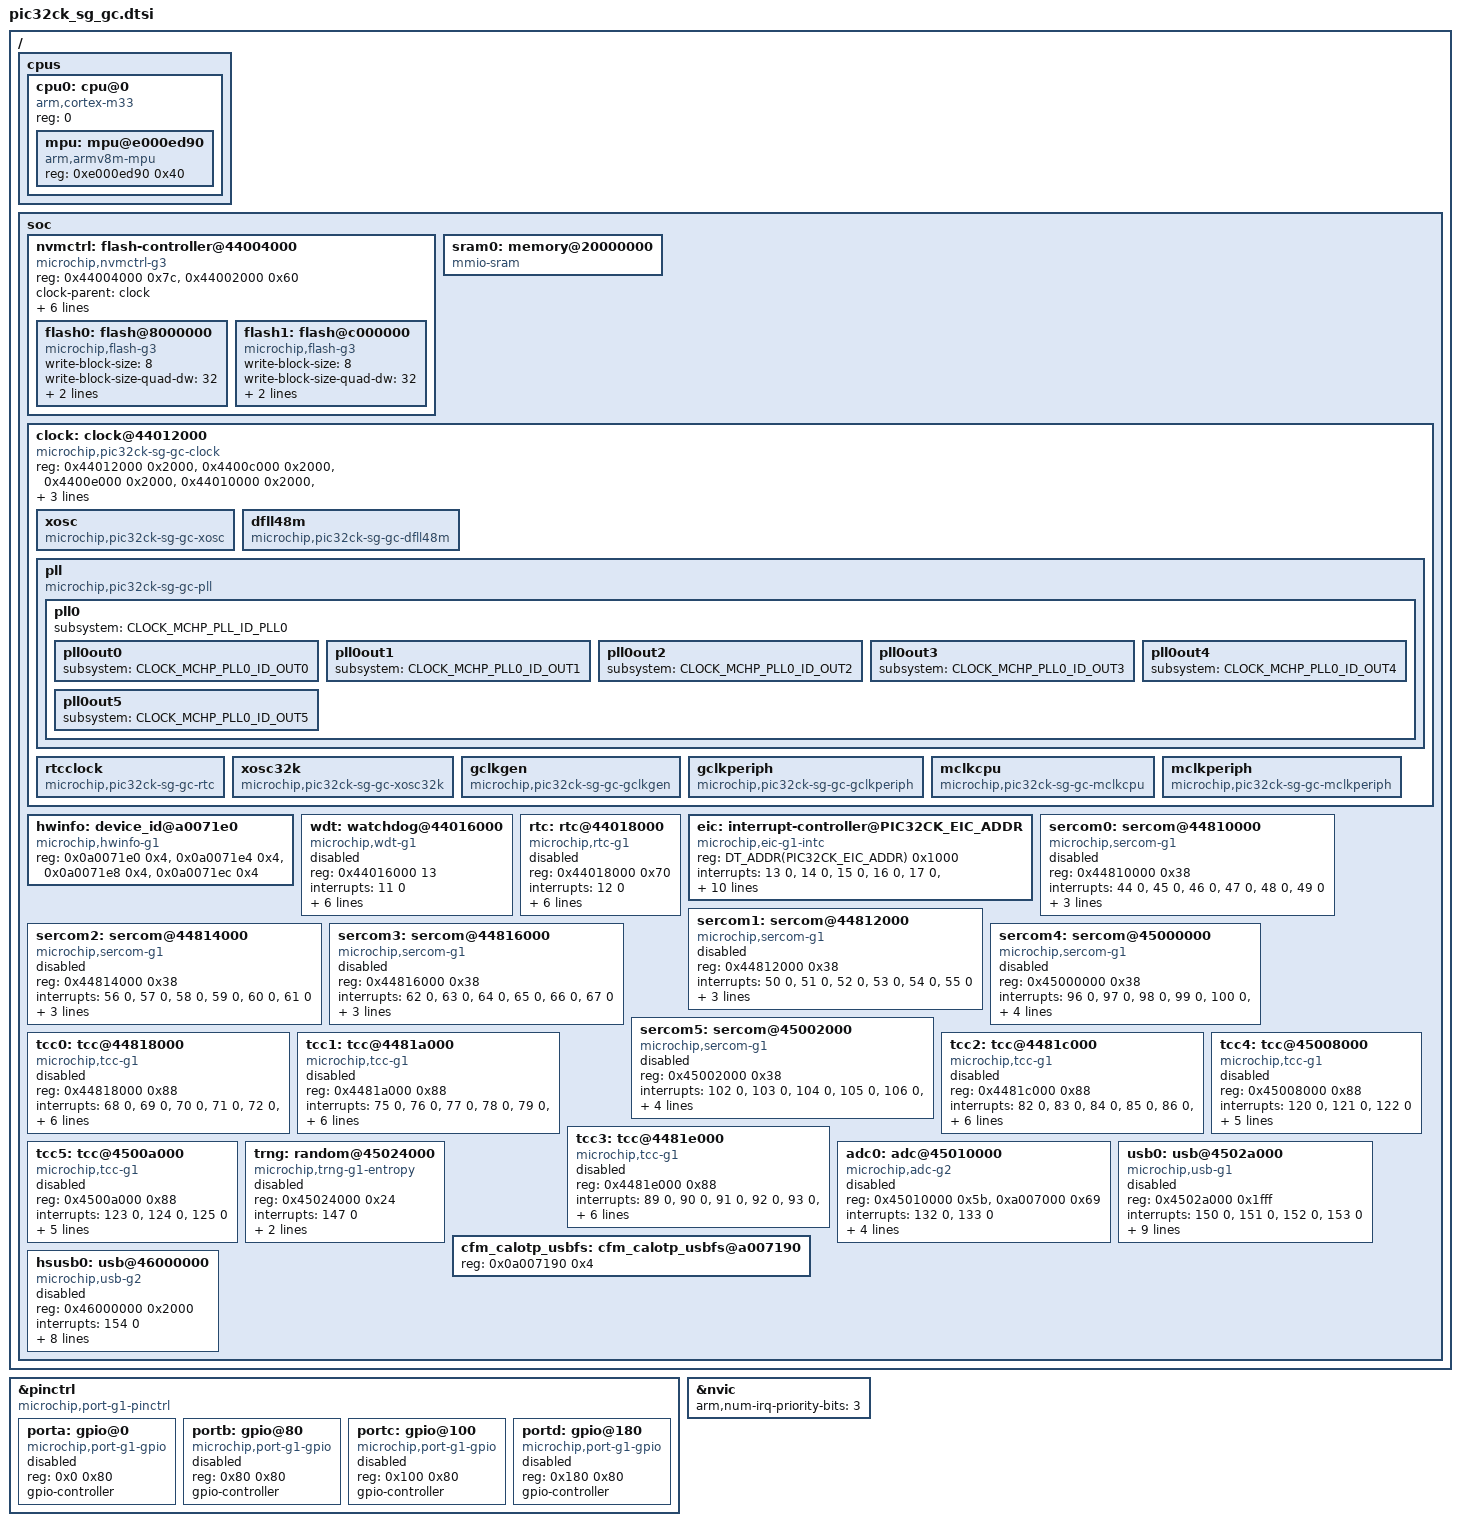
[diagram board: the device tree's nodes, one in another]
/*
 * Copyright (c) 2026 Microchip Technology Inc.
 *
 * SPDX-License-Identifier: Apache-2.0
 */

#include <arm/armv8-m.dtsi>
#include <zephyr/dt-bindings/gpio/gpio.h>
#include <zephyr/dt-bindings/clock/mchp_pic32ck_sg_gc_clock.h>

/* EIC alias the CPU uses; SG parts override it with the secure one (pic32ck_sg.dtsi). */
#ifndef PIC32CK_EIC_ADDR
#define PIC32CK_EIC_ADDR 4401a000
#endif

/ {
	cpus {
		#address-cells = <1>;
		#size-cells = <0>;

		cpu0: cpu@0 {
			device_type = "cpu";
			compatible = "arm,cortex-m33";
			reg = <0>;
			#address-cells = <1>;
			#size-cells = <1>;

			mpu: mpu@e000ed90 {
				compatible = "arm,armv8m-mpu";
				reg = <0xe000ed90 0x40>; /* 64 bytes for ARMv8-M MPU */
			};
		};
	};

	soc {
		nvmctrl: flash-controller@44004000 {
			compatible = "microchip,nvmctrl-g3";
			reg = <0x44004000 0x7c>, <0x44002000 0x60>;
			reg-names = "fcw", "fcr";
			clock-parent = <&clock>;
			clocks = <&mclkperiph CLOCK_MCHP_MCLKPERIPH_ID_FCW_AHB>,
				 <&mclkperiph CLOCK_MCHP_MCLKPERIPH_ID_FCW_APB>,
				 <&mclkperiph CLOCK_MCHP_MCLKPERIPH_ID_FCR_AHB>,
				 <&mclkperiph CLOCK_MCHP_MCLKPERIPH_ID_FCR_APB>;
			clock-names = "mclk-fcw-ahb", "mclk-fcw-apb", "mclk-fcr-ahb",
				      "mclk-fcr-apb";
			interrupts = <0 0>, <1 0>, <2 0>;
			interrupt-names = "eccerr", "crcerr", "fcw";
			#address-cells = <1>;
			#size-cells = <1>;
			ranges;

			/*
			 * BFM and PFM are separate flash devices sharing the
			 * controller, so they are microchip,flash-g3 but not
			 * soc-nv-flash: partitions then resolve to the bank
			 * they live in.
			 */
			flash0: flash@8000000 {
				compatible = "microchip,flash-g3";
				write-block-size = <8>;
				write-block-size-quad-dw = <32>;
				write-block-size-row = <DT_SIZE_K(1)>;
				erase-block-size = <DT_SIZE_K(4)>;
				#address-cells = <1>;
				#size-cells = <1>;
			};

			flash1: flash@c000000 {
				compatible = "microchip,flash-g3";
				write-block-size = <8>;
				write-block-size-quad-dw = <32>;
				write-block-size-row = <DT_SIZE_K(1)>;
				erase-block-size = <DT_SIZE_K(4)>;
				#address-cells = <1>;
				#size-cells = <1>;
			};
		};

		sram0: memory@20000000 {
			compatible = "mmio-sram";
		};

		clock: clock@44012000 {
			compatible = "microchip,pic32ck-sg-gc-clock";
			reg = <0x44012000 0x2000>, <0x4400c000 0x2000>, <0x4400e000 0x2000>,
			      <0x44010000 0x2000>, <0x44008000 0x2000>;
			reg-names = "mclk", "oscctrl", "osc32kctrl", "gclk", "supc";
			interrupts = <5 0>, <5 0>, <5 0>, <6 0>, <6 0>,
				     <6 0>, <6 0>, <6 0>, <6 0>,
				     <7 0>, <8 0>, <8 0>, <9 0>;
			interrupt-names = "xosc-fail", "xosc-crdy", "clk-fail", "dfll-rdy",
					  "dfll-lock", "dfll-ovf", "dfll-unf", "dfll-rcs",
					  "dfll-fail", "pll0-ckr", "xosc32k-rdy", "xosc32k-fail",
					  "ckrdy";

			xosc: xosc {
				compatible = "microchip,pic32ck-sg-gc-xosc";
			};

			dfll48m: dfll48m {
				compatible = "microchip,pic32ck-sg-gc-dfll48m";
			};

			pll: pll {
				compatible = "microchip,pic32ck-sg-gc-pll";

				pll0: pll0 {
					subsystem = <CLOCK_MCHP_PLL_ID_PLL0>;

					pll0out0: pll0out0 {
						subsystem = <CLOCK_MCHP_PLL0_ID_OUT0>;
					};

					pll0out1: pll0out1 {
						subsystem = <CLOCK_MCHP_PLL0_ID_OUT1>;
					};

					pll0out2: pll0out2 {
						subsystem = <CLOCK_MCHP_PLL0_ID_OUT2>;
					};

					pll0out3: pll0out3 {
						subsystem = <CLOCK_MCHP_PLL0_ID_OUT3>;
					};

					pll0out4: pll0out4 {
						subsystem = <CLOCK_MCHP_PLL0_ID_OUT4>;
					};

					pll0out5: pll0out5 {
						subsystem = <CLOCK_MCHP_PLL0_ID_OUT5>;
					};
				};
			};

			rtcclock: rtcclock {
				compatible = "microchip,pic32ck-sg-gc-rtc";
				#clock-cells = <1>;
			};

			xosc32k: xosc32k {
				compatible = "microchip,pic32ck-sg-gc-xosc32k";
			};

			gclkgen: gclkgen {
				compatible = "microchip,pic32ck-sg-gc-gclkgen";
			};

			gclkperiph: gclkperiph {
				compatible = "microchip,pic32ck-sg-gc-gclkperiph";
				#clock-cells = <1>;
			};

			mclkcpu: mclkcpu {
				compatible = "microchip,pic32ck-sg-gc-mclkcpu";
			};

			mclkperiph: mclkperiph {
				compatible = "microchip,pic32ck-sg-gc-mclkperiph";
				#clock-cells = <1>;
			};
		};

		hwinfo: device_id@a0071e0 {
			compatible = "microchip,hwinfo-g1";
			reg = <0x0a0071e0 0x4>,
			      <0x0a0071e4 0x4>,
			      <0x0a0071e8 0x4>,
			      <0x0a0071ec 0x4>;
		};

		wdt: watchdog@44016000 {
			compatible = "microchip,wdt-g1";
			reg = <0x44016000 13>;
			interrupts = <11 0>;
			interrupt-names = "wdt-ew";
			clocks = <&mclkperiph CLOCK_MCHP_MCLKPERIPH_ID_WDT_APB>;
			clock-names = "mclk";
			max-installable-timeout-count = <1>;
			max-timeout-window = <0x4000>;
			max-timeout-window-mode = <0x8000>;
			min-window-limit = <0x8>;
			status = "disabled";
		};

		rtc: rtc@44018000 {
			compatible = "microchip,rtc-g1";
			reg = <0x44018000 0x70>;
			interrupts = <12 0>;
			clocks = <&mclkperiph CLOCK_MCHP_MCLKPERIPH_ID_RTC_APB>,
				 <&rtcclock CLOCK_MCHP_RTC_ID>;
			clock-names = "mclk", "rtcclk";
			prescaler = <1>;
			alarms-count = <2>;
			cal-constant = <1048576>;
			status = "disabled";
		};

		eic: interrupt-controller@PIC32CK_EIC_ADDR {
			compatible = "microchip,eic-g1-intc";
			reg = <DT_ADDR(PIC32CK_EIC_ADDR) 0x1000>;
			interrupts = <13 0>, <14 0>, <15 0>, <16 0>,
				     <17 0>, <18 0>, <19 0>, <20 0>,
				     <21 0>, <22 0>, <23 0>, <24 0>,
				     <25 0>, <26 0>, <27 0>, <28 0>;
			interrupt-names = "extint-0", "extint-1", "extint-2", "extint-3",
					  "extint-4", "extint-5", "extint-6", "extint-7",
					  "extint-8", "extint-9", "extint-10", "extint-11",
					  "extint-12", "extint-13", "extint-14", "extint-15";
			clocks = <&mclkperiph CLOCK_MCHP_MCLKPERIPH_ID_EIC_APB>,
				 <&gclkperiph CLOCK_MCHP_GCLKPERIPH_ID_EIC>;
			clock-names = "mclk", "gclk";
			low-power-mode;
			/* Created this by listing down the mapping between eic lines and the port
			 * and pin numbers available in the pic32ck sg and gc family datasheet.
			 * The set bits are commented beside the values
			 */
			porta-unsupported-pins = <0xe0080000>; /*19|29|30|31*/
			portc-unsupported-pins = <0x00000100>; /*8*/

			/* portd pins -1|2|5|6|7|8|9|10|11|12|13|14|15|16|17|18|19|20|21*/
			portd-supported-pins = <0x003f7ffe>;

			porta-special-pins-1 = <0x1 0xe>; /*0*/
		};

		sercom0: sercom@44810000 {
			compatible = "microchip,sercom-g1";
			reg = <0x44810000 0x38>;
			interrupts = <44 0>, <45 0>, <46 0>, <47 0>, <48 0>, <49 0>;
			interrupt-names = "error", "dre", "txc", "rxc", "rxs", "ctsic";
			clocks = <&mclkperiph CLOCK_MCHP_MCLKPERIPH_ID_SERCOM0_APB>,
				 <&gclkperiph CLOCK_MCHP_GCLKPERIPH_ID_SERCOM0_CORE>;
			clock-names = "mclk", "gclk";
			status = "disabled";
		};

		sercom1: sercom@44812000 {
			compatible = "microchip,sercom-g1";
			reg = <0x44812000 0x38>;
			interrupts = <50 0>, <51 0>, <52 0>, <53 0>, <54 0>, <55 0>;
			interrupt-names = "error", "dre", "txc", "rxc", "rxs", "ctsic";
			clocks = <&mclkperiph CLOCK_MCHP_MCLKPERIPH_ID_SERCOM1_APB>,
				 <&gclkperiph CLOCK_MCHP_GCLKPERIPH_ID_SERCOM1_CORE>;
			clock-names = "mclk", "gclk";
			status = "disabled";
		};

		sercom2: sercom@44814000 {
			compatible = "microchip,sercom-g1";
			reg = <0x44814000 0x38>;
			interrupts = <56 0>, <57 0>, <58 0>, <59 0>, <60 0>, <61 0>;
			interrupt-names = "error", "dre", "txc", "rxc", "rxs", "ctsic";
			clocks = <&mclkperiph CLOCK_MCHP_MCLKPERIPH_ID_SERCOM2_APB>,
				 <&gclkperiph CLOCK_MCHP_GCLKPERIPH_ID_SERCOM2_CORE>;
			clock-names = "mclk", "gclk";
			status = "disabled";
		};

		sercom3: sercom@44816000 {
			compatible = "microchip,sercom-g1";
			reg = <0x44816000 0x38>;
			interrupts = <62 0>, <63 0>, <64 0>, <65 0>, <66 0>, <67 0>;
			interrupt-names = "error", "dre", "txc", "rxc", "rxs", "ctsic";
			clocks = <&mclkperiph CLOCK_MCHP_MCLKPERIPH_ID_SERCOM3_APB>,
				 <&gclkperiph CLOCK_MCHP_GCLKPERIPH_ID_SERCOM3_CORE>;
			clock-names = "mclk", "gclk";
			status = "disabled";
		};

		sercom4: sercom@45000000 {
			compatible = "microchip,sercom-g1";
			reg = <0x45000000 0x38>;
			interrupts = <96 0>, <97 0>, <98 0>, <99 0>, <100 0>, <101 0>;
			interrupt-names = "error", "dre", "txc", "rxc", "rxs", "ctsic";
			clocks = <&mclkperiph CLOCK_MCHP_MCLKPERIPH_ID_SERCOM4_APB>,
				 <&gclkperiph CLOCK_MCHP_GCLKPERIPH_ID_SERCOM4_CORE>;
			clock-names = "mclk", "gclk";
			status = "disabled";
		};

		sercom5: sercom@45002000 {
			compatible = "microchip,sercom-g1";
			reg = <0x45002000 0x38>;
			interrupts = <102 0>, <103 0>, <104 0>, <105 0>, <106 0>, <107 0>;
			interrupt-names = "error", "dre", "txc", "rxc", "rxs", "ctsic";
			clocks = <&mclkperiph CLOCK_MCHP_MCLKPERIPH_ID_SERCOM5_APB>,
				 <&gclkperiph CLOCK_MCHP_GCLKPERIPH_ID_SERCOM5_CORE>;
			clock-names = "mclk", "gclk";
			status = "disabled";
		};

		tcc0: tcc@44818000 {
			compatible = "microchip,tcc-g1";
			reg = <0x44818000 0x88>;
			interrupts = <68 0>, <69 0>, <70 0>, <71 0>, <72 0>, <73 0>, <74 0>;
			interrupt-names = "cnt", "mc0", "mc1", "mc2", "mc3", "mc4", "mc5";
			clocks = <&mclkperiph CLOCK_MCHP_MCLKPERIPH_ID_TCC0_APB>,
				 <&gclkperiph CLOCK_MCHP_GCLKPERIPH_ID_TCC0>;
			clock-names = "mclk", "gclk";
			max-bit-width = <32>;
			channels = <6>;
			status = "disabled";
		};

		tcc1: tcc@4481a000 {
			compatible = "microchip,tcc-g1";
			reg = <0x4481a000 0x88>;
			interrupts = <75 0>, <76 0>, <77 0>, <78 0>, <79 0>, <80 0>, <81 0>;
			interrupt-names = "cnt", "mc0", "mc1", "mc2", "mc3", "mc4", "mc5";
			clocks = <&mclkperiph CLOCK_MCHP_MCLKPERIPH_ID_TCC1_APB>,
				 <&gclkperiph CLOCK_MCHP_GCLKPERIPH_ID_TCC1>;
			clock-names = "mclk", "gclk";
			max-bit-width = <32>;
			channels = <6>;
			status = "disabled";
		};

		tcc2: tcc@4481c000 {
			compatible = "microchip,tcc-g1";
			reg = <0x4481c000 0x88>;
			interrupts = <82 0>, <83 0>, <84 0>, <85 0>, <86 0>, <87 0>, <88 0>;
			interrupt-names = "cnt", "mc0", "mc1", "mc2", "mc3", "mc4", "mc5";
			clocks = <&mclkperiph CLOCK_MCHP_MCLKPERIPH_ID_TCC2_APB>,
				 <&gclkperiph CLOCK_MCHP_GCLKPERIPH_ID_TCC2>;
			clock-names = "mclk", "gclk";
			max-bit-width = <32>;
			channels = <6>;
			status = "disabled";
		};

		tcc3: tcc@4481e000 {
			compatible = "microchip,tcc-g1";
			reg = <0x4481e000 0x88>;
			interrupts = <89 0>, <90 0>, <91 0>, <92 0>, <93 0>, <94 0>, <95 0>;
			interrupt-names = "cnt", "mc0", "mc1", "mc2", "mc3", "mc4", "mc5";
			clocks = <&mclkperiph CLOCK_MCHP_MCLKPERIPH_ID_TCC3_APB>,
				 <&gclkperiph CLOCK_MCHP_GCLKPERIPH_ID_TCC3>;
			clock-names = "mclk", "gclk";
			max-bit-width = <32>;
			channels = <6>;
			status = "disabled";
		};

		tcc4: tcc@45008000 {
			compatible = "microchip,tcc-g1";
			reg = <0x45008000 0x88>;
			interrupts = <120 0>, <121 0>, <122 0>;
			interrupt-names = "cnt", "mc0", "mc1";
			clocks = <&mclkperiph CLOCK_MCHP_MCLKPERIPH_ID_TCC4_APB>,
				 <&gclkperiph CLOCK_MCHP_GCLKPERIPH_ID_TCC4>;
			clock-names = "mclk", "gclk";
			max-bit-width = <16>;
			channels = <2>;
			status = "disabled";
		};

		tcc5: tcc@4500a000 {
			compatible = "microchip,tcc-g1";
			reg = <0x4500a000 0x88>;
			interrupts = <123 0>, <124 0>, <125 0>;
			interrupt-names = "cnt", "mc0", "mc1";
			clocks = <&mclkperiph CLOCK_MCHP_MCLKPERIPH_ID_TCC5_APB>,
				 <&gclkperiph CLOCK_MCHP_GCLKPERIPH_ID_TCC5>;
			clock-names = "mclk", "gclk";
			max-bit-width = <16>;
			channels = <2>;
			status = "disabled";
		};

		trng: random@45024000 {
			compatible = "microchip,trng-g1-entropy";
			reg = <0x45024000 0x24>;
			interrupts = <147 0>;
			interrupt-names = "datardy";
			clocks = <&mclkperiph CLOCK_MCHP_MCLKPERIPH_ID_TRNG_APB>;
			clock-names = "mclk";
			status = "disabled";
		};

		adc0: adc@45010000 {
			compatible = "microchip,adc-g2";
			reg = <0x45010000 0x5b>, <0xa007000 0x69>;
			reg-names = "adc", "fuses";
			interrupts = <132 0>, <133 0>;
			interrupt-names = "global", "core0";
			num-channels = <14>;
			#io-channel-cells = <1>;
			clocks = <&mclkperiph CLOCK_MCHP_MCLKPERIPH_ID_ADC_APB>,
				 <&gclkperiph CLOCK_MCHP_GCLKPERIPH_ID_ADC>;
			clock-names = "mclk", "gclk";
			status = "disabled";
		};

		/* CFM CAL OTP region containing calibration data for USB */
		cfm_calotp_usbfs: cfm_calotp_usbfs@a007190 {
			reg = <0x0a007190 0x4>;
		};

		usb0: usb@4502a000 {
			compatible = "microchip,usb-g1";
			reg = <0x4502a000 0x1fff>;
			interrupts = <150 0>, <151 0>, <152 0>, <153 0>;
			interrupt-names = "usb", "sof", "trcpt0", "trcpt1";
			num-bidir-endpoints = <8>;
			maximum-speed = "full-speed";
			nvm-calib = <&cfm_calotp_usbfs>;
			calib-mapping = <0x06 0x06 0x1f 0x05>,
					<0x0 0x0 0x1f 0x29>,
					<0xc 0xc 0x07 0x03>;
			calib-mapping-names = "TRANSN", "TRANSP", "TRIM";
			clocks = <&mclkperiph CLOCK_MCHP_MCLKPERIPH_ID_USB_APB>,
				 <&gclkperiph CLOCK_MCHP_GCLKPERIPH_ID_USB>;
			clock-names = "mclk", "gclk";
			status = "disabled";
		};

		hsusb0: usb@46000000 {
			compatible = "microchip,usb-g2";
			reg = <0x46000000 0x2000>;
			interrupts = <154 0>;
			clocks = <&mclkperiph CLOCK_MCHP_MCLKPERIPH_ID_USBHS_AHB>,
				 <&mclkperiph CLOCK_MCHP_MCLKPERIPH_ID_USB_APB>,
				 <&gclkperiph CLOCK_MCHP_GCLKPERIPH_ID_USB>;
			clock-names = "ahb", "apb", "gclk";
			num-bidir-endpoints = <8>;
			num-in-endpoints = <8>;
			num-out-endpoints = <8>;
			maximum-speed = "high-speed";
			status = "disabled";
		};
	};
};

&pinctrl {
	compatible = "microchip,port-g1-pinctrl";
	#address-cells = <1>;
	#size-cells = <1>;

	porta: gpio@0 {
		compatible = "microchip,port-g1-gpio";
		reg = <0x0 0x80>;
		gpio-controller;
		#gpio-cells = <2>;
		#microchip,pin-cells = <2>;
		status = "disabled";
	};

	portb: gpio@80 {
		compatible = "microchip,port-g1-gpio";
		reg = <0x80 0x80>;
		gpio-controller;
		#gpio-cells = <2>;
		#microchip,pin-cells = <2>;
		status = "disabled";
	};

	portc: gpio@100 {
		compatible = "microchip,port-g1-gpio";
		reg = <0x100 0x80>;
		gpio-controller;
		#gpio-cells = <2>;
		#microchip,pin-cells = <2>;
		status = "disabled";
	};

	portd: gpio@180 {
		compatible = "microchip,port-g1-gpio";
		reg = <0x180 0x80>;
		gpio-controller;
		#gpio-cells = <2>;
		#microchip,pin-cells = <2>;
		status = "disabled";
	};
};

&nvic {
	arm,num-irq-priority-bits = <3>;
};
